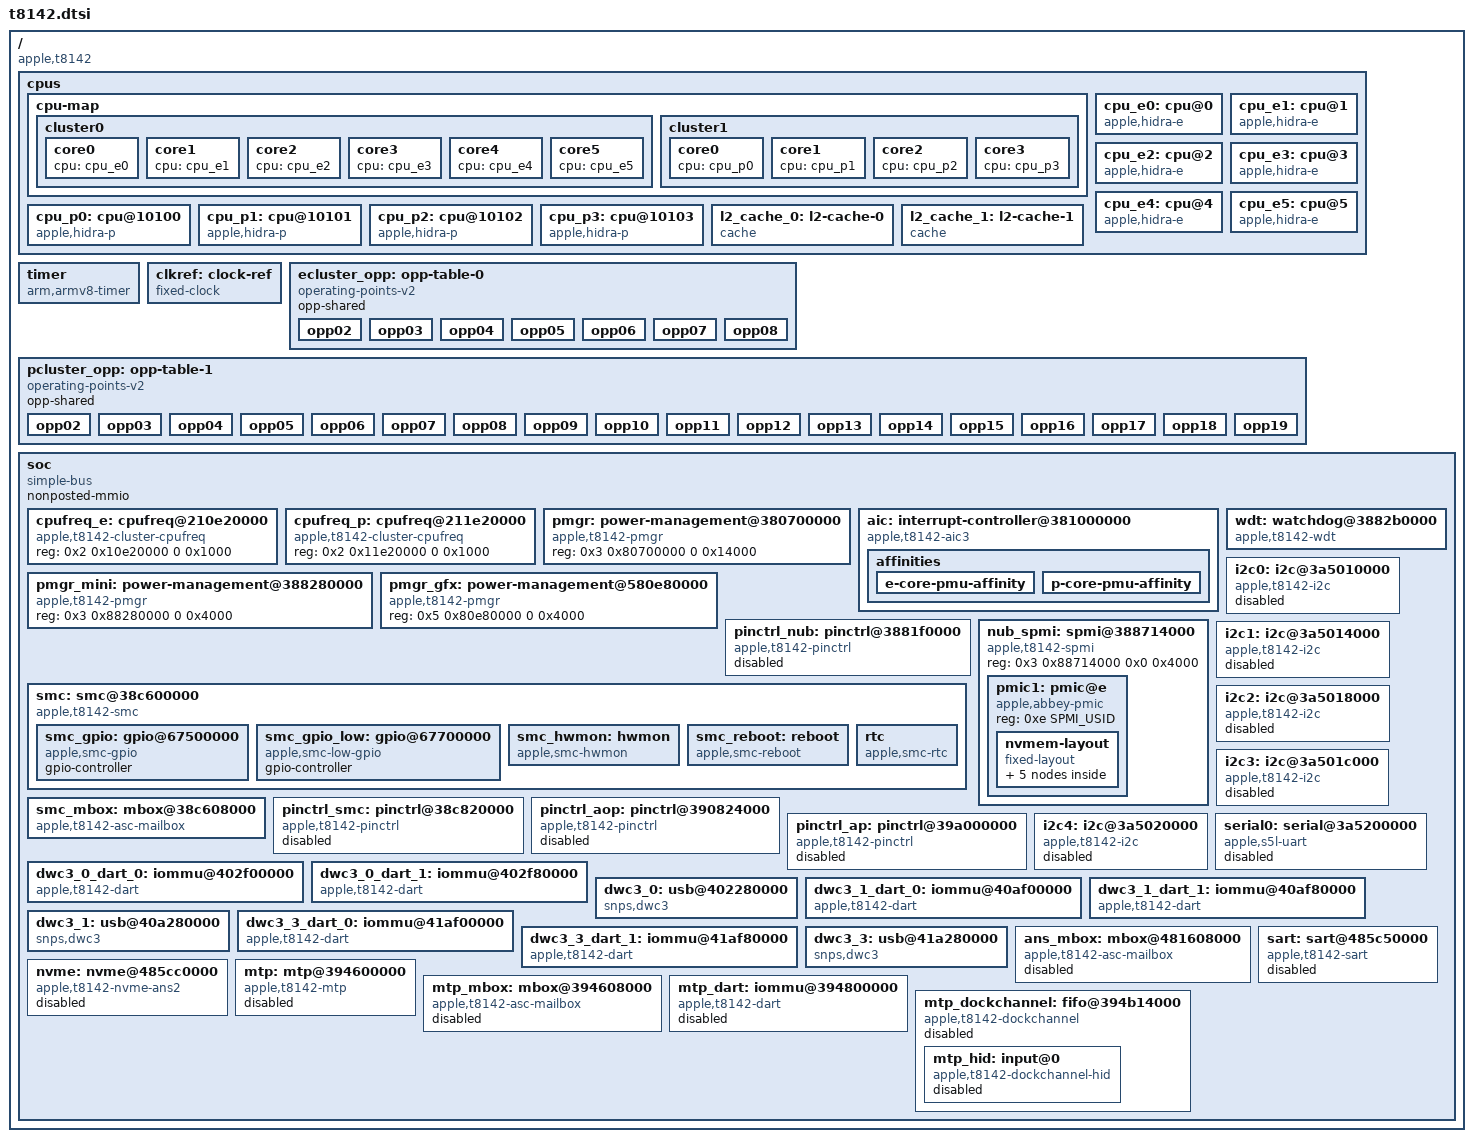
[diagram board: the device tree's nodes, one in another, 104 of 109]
// SPDX-License-Identifier: GPL-2.0+ OR MIT
/*
 * Apple T8142 "M5" SoC
 *
 * Minimal bring-up tree derived from the J704 ADT (macOS 27.0) and t8132.dtsi.
 * Power domains come from t8142-pmgr.dtsi (generated from the ADT).
 */

#include <dt-bindings/interrupt-controller/apple-aic.h>
#include <dt-bindings/interrupt-controller/irq.h>
#include <dt-bindings/pinctrl/apple.h>
#include <dt-bindings/spmi/spmi.h>

/ {
	compatible = "apple,t8142", "apple,arm-platform";

	#address-cells = <2>;
	#size-cells = <2>;

	cpus {
		#address-cells = <2>;
		#size-cells = <0>;

		cpu-map {
			cluster0 {
				core0 {
					cpu = <&cpu_e0>;
				};
				core1 {
					cpu = <&cpu_e1>;
				};
				core2 {
					cpu = <&cpu_e2>;
				};
				core3 {
					cpu = <&cpu_e3>;
				};
				core4 {
					cpu = <&cpu_e4>;
				};
				core5 {
					cpu = <&cpu_e5>;
				};
			};

			cluster1 {
				core0 {
					cpu = <&cpu_p0>;
				};
				core1 {
					cpu = <&cpu_p1>;
				};
				core2 {
					cpu = <&cpu_p2>;
				};
				core3 {
					cpu = <&cpu_p3>;
				};
			};
		};

		cpu_e0: cpu@0 {
			compatible = "apple,hidra-e";
			device_type = "cpu";
			reg = <0x0 0x0>;
			enable-method = "spin-table";
			cpu-release-addr = <0 0>; /* to be filled by loader */
			operating-points-v2 = <&ecluster_opp>;
			performance-domains = <&cpufreq_e>;
			next-level-cache = <&l2_cache_0>;
		};

		cpu_e1: cpu@1 {
			compatible = "apple,hidra-e";
			device_type = "cpu";
			reg = <0x0 0x1>;
			enable-method = "spin-table";
			cpu-release-addr = <0 0>;
			operating-points-v2 = <&ecluster_opp>;
			performance-domains = <&cpufreq_e>;
			next-level-cache = <&l2_cache_0>;
		};

		cpu_e2: cpu@2 {
			compatible = "apple,hidra-e";
			device_type = "cpu";
			reg = <0x0 0x2>;
			enable-method = "spin-table";
			cpu-release-addr = <0 0>;
			operating-points-v2 = <&ecluster_opp>;
			performance-domains = <&cpufreq_e>;
			next-level-cache = <&l2_cache_0>;
		};

		cpu_e3: cpu@3 {
			compatible = "apple,hidra-e";
			device_type = "cpu";
			reg = <0x0 0x3>;
			enable-method = "spin-table";
			cpu-release-addr = <0 0>;
			operating-points-v2 = <&ecluster_opp>;
			performance-domains = <&cpufreq_e>;
			next-level-cache = <&l2_cache_0>;
		};

		cpu_e4: cpu@4 {
			compatible = "apple,hidra-e";
			device_type = "cpu";
			reg = <0x0 0x4>;
			enable-method = "spin-table";
			cpu-release-addr = <0 0>;
			operating-points-v2 = <&ecluster_opp>;
			performance-domains = <&cpufreq_e>;
			next-level-cache = <&l2_cache_0>;
		};

		cpu_e5: cpu@5 {
			compatible = "apple,hidra-e";
			device_type = "cpu";
			reg = <0x0 0x5>;
			enable-method = "spin-table";
			cpu-release-addr = <0 0>;
			operating-points-v2 = <&ecluster_opp>;
			performance-domains = <&cpufreq_e>;
			next-level-cache = <&l2_cache_0>;
		};

		cpu_p0: cpu@10100 {
			compatible = "apple,hidra-p";
			device_type = "cpu";
			reg = <0x0 0x10100>;
			enable-method = "spin-table";
			cpu-release-addr = <0 0>;
			operating-points-v2 = <&pcluster_opp>;
			performance-domains = <&cpufreq_p>;
			next-level-cache = <&l2_cache_1>;
		};

		cpu_p1: cpu@10101 {
			compatible = "apple,hidra-p";
			device_type = "cpu";
			reg = <0x0 0x10101>;
			enable-method = "spin-table";
			cpu-release-addr = <0 0>;
			operating-points-v2 = <&pcluster_opp>;
			performance-domains = <&cpufreq_p>;
			next-level-cache = <&l2_cache_1>;
		};

		cpu_p2: cpu@10102 {
			compatible = "apple,hidra-p";
			device_type = "cpu";
			reg = <0x0 0x10102>;
			enable-method = "spin-table";
			cpu-release-addr = <0 0>;
			operating-points-v2 = <&pcluster_opp>;
			performance-domains = <&cpufreq_p>;
			next-level-cache = <&l2_cache_1>;
		};

		cpu_p3: cpu@10103 {
			compatible = "apple,hidra-p";
			device_type = "cpu";
			reg = <0x0 0x10103>;
			enable-method = "spin-table";
			cpu-release-addr = <0 0>;
			operating-points-v2 = <&pcluster_opp>;
			performance-domains = <&cpufreq_p>;
			next-level-cache = <&l2_cache_1>;
		};

		l2_cache_0: l2-cache-0 {
			compatible = "cache";
			cache-level = <2>;
			cache-unified;
			cache-size = <0x600000>;
		};

		l2_cache_1: l2-cache-1 {
			compatible = "cache";
			cache-level = <2>;
			cache-unified;
			cache-size = <0x1000000>;
		};
	};

	timer {
		compatible = "arm,armv8-timer";
		interrupt-parent = <&aic>;
		interrupt-names = "phys", "virt", "hyp-phys", "hyp-virt";
		interrupts = <AIC_FIQ AIC_TMR_GUEST_PHYS IRQ_TYPE_LEVEL_HIGH>,
		             <AIC_FIQ AIC_TMR_GUEST_VIRT IRQ_TYPE_LEVEL_HIGH>,
		             <AIC_FIQ AIC_TMR_HV_PHYS IRQ_TYPE_LEVEL_HIGH>,
		             <AIC_FIQ AIC_TMR_HV_VIRT IRQ_TYPE_LEVEL_HIGH>;
	};

	clkref: clock-ref {
		compatible = "fixed-clock";
		#clock-cells = <0>;
		clock-frequency = <24000000>;
		clock-output-names = "clkref";
	};

	/*
	 * DVFS states from the ADT (/arm-io/pmgr voltage-states1-sram for the E
	 * cluster, voltage-states5-sram for the P cluster); opp-level = P-state.
	 * clock-latency-ns is a conservative estimate, not measured.
	 * P-state 1 is left out: with the ADT's 972/1308 MHz it benchmarks like
	 * ~320-330 MHz on both clusters (#244), unlike states 2+ which scale linearly.
	 * The P cluster also clamps requests above P-state 15 (4272 MHz) here.
	 */
	ecluster_opp: opp-table-0 {
		compatible = "operating-points-v2";
		opp-shared;

		opp02 {
			opp-hz = /bits/ 64 <1152000000>;
			opp-level = <2>;
			clock-latency-ns = <50000>;
		};

		opp03 {
			opp-hz = /bits/ 64 <1584000000>;
			opp-level = <3>;
			clock-latency-ns = <50000>;
		};

		opp04 {
			opp-hz = /bits/ 64 <1992000000>;
			opp-level = <4>;
			clock-latency-ns = <50000>;
		};

		opp05 {
			opp-hz = /bits/ 64 <2352000000>;
			opp-level = <5>;
			clock-latency-ns = <50000>;
		};

		opp06 {
			opp-hz = /bits/ 64 <2700000000>;
			opp-level = <6>;
			clock-latency-ns = <50000>;
		};

		opp07 {
			opp-hz = /bits/ 64 <2964000000>;
			opp-level = <7>;
			clock-latency-ns = <50000>;
		};

		opp08 {
			opp-hz = /bits/ 64 <3048000000>;
			opp-level = <8>;
			clock-latency-ns = <50000>;
		};
	};

	pcluster_opp: opp-table-1 {
		compatible = "operating-points-v2";
		opp-shared;

		opp02 {
			opp-hz = /bits/ 64 <1608000000>;
			opp-level = <2>;
			clock-latency-ns = <50000>;
		};

		opp03 {
			opp-hz = /bits/ 64 <1932000000>;
			opp-level = <3>;
			clock-latency-ns = <50000>;
		};

		opp04 {
			opp-hz = /bits/ 64 <2220000000>;
			opp-level = <4>;
			clock-latency-ns = <50000>;
		};

		opp05 {
			opp-hz = /bits/ 64 <2508000000>;
			opp-level = <5>;
			clock-latency-ns = <50000>;
		};

		opp06 {
			opp-hz = /bits/ 64 <2820000000>;
			opp-level = <6>;
			clock-latency-ns = <50000>;
		};

		opp07 {
			opp-hz = /bits/ 64 <3072000000>;
			opp-level = <7>;
			clock-latency-ns = <50000>;
		};

		opp08 {
			opp-hz = /bits/ 64 <3300000000>;
			opp-level = <8>;
			clock-latency-ns = <50000>;
		};

		opp09 {
			opp-hz = /bits/ 64 <3516000000>;
			opp-level = <9>;
			clock-latency-ns = <50000>;
		};

		opp10 {
			opp-hz = /bits/ 64 <3720000000>;
			opp-level = <10>;
			clock-latency-ns = <50000>;
		};

		opp11 {
			opp-hz = /bits/ 64 <3876000000>;
			opp-level = <11>;
			clock-latency-ns = <50000>;
		};

		opp12 {
			opp-hz = /bits/ 64 <4020000000>;
			opp-level = <12>;
			clock-latency-ns = <50000>;
		};

		opp13 {
			opp-hz = /bits/ 64 <4176000000>;
			opp-level = <13>;
			clock-latency-ns = <50000>;
		};

		opp14 {
			opp-hz = /bits/ 64 <4248000000>;
			opp-level = <14>;
			clock-latency-ns = <50000>;
		};

		opp15 {
			opp-hz = /bits/ 64 <4272000000>;
			opp-level = <15>;
			clock-latency-ns = <50000>;
		};

		opp16 {
			opp-hz = /bits/ 64 <4332000000>;
			opp-level = <16>;
			clock-latency-ns = <50000>;
		};

		opp17 {
			opp-hz = /bits/ 64 <4428000000>;
			opp-level = <17>;
			clock-latency-ns = <50000>;
		};

		opp18 {
			opp-hz = /bits/ 64 <4512000000>;
			opp-level = <18>;
			clock-latency-ns = <50000>;
		};

		opp19 {
			opp-hz = /bits/ 64 <4608000000>;
			opp-level = <19>;
			clock-latency-ns = <50000>;
		};
	};

	soc: soc {
		compatible = "simple-bus";
		#address-cells = <2>;
		#size-cells = <2>;

		ranges;
		nonposted-mmio;

		cpufreq_e: cpufreq@210e20000 {
			compatible = "apple,t8142-cluster-cpufreq", "apple,t8112-cluster-cpufreq",
				     "apple,cluster-cpufreq";
			reg = <0x2 0x10e20000 0 0x1000>;
			#performance-domain-cells = <0>;
		};

		cpufreq_p: cpufreq@211e20000 {
			compatible = "apple,t8142-cluster-cpufreq", "apple,t8112-cluster-cpufreq",
				     "apple,cluster-cpufreq";
			reg = <0x2 0x11e20000 0 0x1000>;
			#performance-domain-cells = <0>;
		};

		pmgr: power-management@380700000 {
			compatible = "apple,t8142-pmgr", "apple,t8103-pmgr", "syscon", "simple-mfd";
			#address-cells = <1>;
			#size-cells = <1>;
			reg = <0x3 0x80700000 0 0x14000>;
		};

		aic: interrupt-controller@381000000 {
			compatible = "apple,t8142-aic3", "apple,t8122-aic3";
			#interrupt-cells = <3>;
			interrupt-controller;
			reg = <0x00000003 0x81000000 0x00000000 0x1cc000>,
			      <0x00000003 0x81040000 0x00000000 0x4000>;
			reg-names = "core", "event";
			power-domains = <&ps_aic>;

			affinities {
				e-core-pmu-affinity {
					apple,fiq-index = <AIC_CPU_PMU_E>;
					cpus = <&cpu_e0 &cpu_e1 &cpu_e2 &cpu_e3 &cpu_e4 &cpu_e5>;
				};

				p-core-pmu-affinity {
					apple,fiq-index = <AIC_CPU_PMU_P>;
					cpus = <&cpu_p0 &cpu_p1 &cpu_p2 &cpu_p3>;
				};
			};
		};

		pmgr_mini: power-management@388280000 {
			compatible = "apple,t8142-pmgr", "apple,t8103-pmgr", "syscon", "simple-mfd";
			#address-cells = <1>;
			#size-cells = <1>;
			reg = <0x3 0x88280000 0 0x4000>;
		};

		pmgr_gfx: power-management@580e80000 {
			compatible = "apple,t8142-pmgr", "apple,t8103-pmgr", "syscon", "simple-mfd";
			#address-cells = <1>;
			#size-cells = <1>;
			reg = <0x5 0x80e80000 0 0x4000>;
		};

		wdt: watchdog@3882b0000 {
			compatible = "apple,t8142-wdt", "apple,t8103-wdt";
			reg = <0x3 0x882b0000 0x0 0x4000>;
			clocks = <&clkref>;
			interrupt-parent = <&aic>;
			interrupts = <AIC_IRQ 361 IRQ_TYPE_LEVEL_HIGH>;
		};

		pinctrl_nub: pinctrl@3881f0000 {
			compatible = "apple,t8142-pinctrl", "apple,t8103-pinctrl";
			reg = <0x3 0x881f0000 0x0 0x4000>;
			power-domains = <&ps_nub_gpio>;

			gpio-controller;
			#gpio-cells = <2>;
			gpio-ranges = <&pinctrl_nub 0 0 32>;
			apple,npins = <32>;

			interrupt-controller;
			#interrupt-cells = <2>;
			interrupt-parent = <&aic>;
			interrupts = <AIC_IRQ 574 IRQ_TYPE_LEVEL_HIGH>,
			             <AIC_IRQ 575 IRQ_TYPE_LEVEL_HIGH>,
			             <AIC_IRQ 576 IRQ_TYPE_LEVEL_HIGH>,
			             <AIC_IRQ 577 IRQ_TYPE_LEVEL_HIGH>,
			             <AIC_IRQ 578 IRQ_TYPE_LEVEL_HIGH>,
			             <AIC_IRQ 579 IRQ_TYPE_LEVEL_HIGH>,
			             <AIC_IRQ 580 IRQ_TYPE_LEVEL_HIGH>;
			status = "disabled"; /* npins unverified on T8142 */
		};

		/*
		 * From the ADT: nub-spmi0 (pmu-main, "pmu,abbey" at USID 0xe) and smc
		 * (ascwrap-v6, IRQs 633-636, shared SRAM = iop-smc-nub region-base/size).
		 * The PMU scratchpad offsets (info-rtc_scrpad 0x2100, info-pm_setting,
		 * info-fault_shadow, info-scrpad_socd, info-leg_scrpad) match t6031.
		 * The legacy scratchpad cells (boot_stage etc.) follow t6031 too
		 * (info-leg_scrpad 0xf800).
		 */
		nub_spmi: spmi@388714000 {
			/* generation 4 (ADT gen = 4): not register compatible with t8103 */
			compatible = "apple,t8142-spmi";
			reg = <0x3 0x88714000 0x0 0x4000>;
			#address-cells = <2>;
			#size-cells = <0>;

			pmic1: pmic@e {
				compatible = "apple,abbey-pmic", "apple,spmi-nvmem";
				reg = <0xe SPMI_USID>;

				nvmem-layout {
					compatible = "fixed-layout";
					#address-cells = <1>;
					#size-cells = <1>;

					rtc_offset: rtc-offset@2100 {
						reg = <0x2100 0x6>;
					};

					boot_stage: boot-stage@f801 {
						reg = <0xf801 0x1>;
					};

					boot_error_count: boot-error-count@f802,0 {
						reg = <0xf802 0x1>;
						bits = <0 4>;
					};

					panic_count: panic-count@f802,4 {
						reg = <0xf802 0x1>;
						bits = <4 4>;
					};

					shutdown_flag: shutdown-flag@f80f,3 {
						reg = <0xf80f 0x1>;
						bits = <3 1>;
					};
				};
			};
		};

		smc: smc@38c600000 {
			compatible = "apple,t8142-smc", "apple,smc";
			reg = <0x3 0x8c600000 0x0 0x4000>,
			      <0x3 0x8de00000 0x0 0x120000>;
			reg-names = "smc", "sram";
			mboxes = <&smc_mbox>;

			smc_gpio: gpio@67500000 {
				compatible = "apple,smc-gpio";
				gpio-controller;
				#gpio-cells = <2>;
			};

			smc_gpio_low: gpio@67700000 {
				compatible = "apple,smc-low-gpio";
				gpio-controller;
				#gpio-cells = <2>;
			};

			smc_hwmon: hwmon {
				compatible = "apple,smc-hwmon";
			};

			smc_reboot: reboot {
				compatible = "apple,smc-reboot";
				nvmem-cells = <&shutdown_flag>, <&boot_stage>,
					      <&boot_error_count>, <&panic_count>;
				nvmem-cell-names = "shutdown_flag", "boot_stage",
						   "boot_error_count", "panic_count";
			};

			rtc {
				compatible = "apple,smc-rtc";
				nvmem-cells = <&rtc_offset>;
				nvmem-cell-names = "rtc_offset";
			};
		};

		smc_mbox: mbox@38c608000 {
			compatible = "apple,t8142-asc-mailbox", "apple,asc-mailbox-v4";
			reg = <0x3 0x8c608000 0x0 0x4000>;
			interrupt-parent = <&aic>;
			interrupts = <AIC_IRQ 633 IRQ_TYPE_LEVEL_HIGH>,
				     <AIC_IRQ 634 IRQ_TYPE_LEVEL_HIGH>,
				     <AIC_IRQ 635 IRQ_TYPE_LEVEL_HIGH>,
				     <AIC_IRQ 636 IRQ_TYPE_LEVEL_HIGH>;
			interrupt-names = "send-empty", "send-not-empty",
					  "recv-empty", "recv-not-empty";
			#mbox-cells = <0>;
		};

		pinctrl_smc: pinctrl@38c820000 {
			compatible = "apple,t8142-pinctrl", "apple,t8103-pinctrl";
			reg = <0x3 0x8c820000 0x0 0x4000>;

			gpio-controller;
			#gpio-cells = <2>;
			gpio-ranges = <&pinctrl_smc 0 0 18>;
			apple,npins = <18>;

			interrupt-controller;
			#interrupt-cells = <2>;
			interrupt-parent = <&aic>;
			interrupts = <AIC_IRQ 624 IRQ_TYPE_LEVEL_HIGH>,
			             <AIC_IRQ 625 IRQ_TYPE_LEVEL_HIGH>,
			             <AIC_IRQ 626 IRQ_TYPE_LEVEL_HIGH>,
			             <AIC_IRQ 627 IRQ_TYPE_LEVEL_HIGH>,
			             <AIC_IRQ 628 IRQ_TYPE_LEVEL_HIGH>,
			             <AIC_IRQ 629 IRQ_TYPE_LEVEL_HIGH>,
			             <AIC_IRQ 630 IRQ_TYPE_LEVEL_HIGH>;
			status = "disabled"; /* npins unverified on T8142 */
		};

		pinctrl_aop: pinctrl@390824000 {
			compatible = "apple,t8142-pinctrl", "apple,t8103-pinctrl";
			reg = <0x3 0x90824000 0x0 0x4000>;

			gpio-controller;
			#gpio-cells = <2>;
			gpio-ranges = <&pinctrl_aop 0 0 57>;
			apple,npins = <57>;

			interrupt-controller;
			#interrupt-cells = <2>;
			interrupt-parent = <&aic>;
			interrupts = <AIC_IRQ 480 IRQ_TYPE_LEVEL_HIGH>,
			             <AIC_IRQ 481 IRQ_TYPE_LEVEL_HIGH>,
			             <AIC_IRQ 482 IRQ_TYPE_LEVEL_HIGH>,
			             <AIC_IRQ 483 IRQ_TYPE_LEVEL_HIGH>,
			             <AIC_IRQ 484 IRQ_TYPE_LEVEL_HIGH>,
			             <AIC_IRQ 485 IRQ_TYPE_LEVEL_HIGH>,
			             <AIC_IRQ 486 IRQ_TYPE_LEVEL_HIGH>;
			status = "disabled"; /* npins unverified on T8142 */
		};

		pinctrl_ap: pinctrl@39a000000 {
			compatible = "apple,t8142-pinctrl", "apple,t8103-pinctrl";
			reg = <0x3 0x9a000000 0x0 0x100000>;
			power-domains = <&ps_gpio>;

			gpio-controller;
			#gpio-cells = <2>;
			gpio-ranges = <&pinctrl_ap 0 0 224>;
			apple,npins = <224>;

			interrupt-controller;
			#interrupt-cells = <2>;
			interrupt-parent = <&aic>;
			interrupts = <AIC_IRQ 347 IRQ_TYPE_LEVEL_HIGH>,
			             <AIC_IRQ 348 IRQ_TYPE_LEVEL_HIGH>,
			             <AIC_IRQ 349 IRQ_TYPE_LEVEL_HIGH>,
			             <AIC_IRQ 350 IRQ_TYPE_LEVEL_HIGH>,
			             <AIC_IRQ 351 IRQ_TYPE_LEVEL_HIGH>,
			             <AIC_IRQ 352 IRQ_TYPE_LEVEL_HIGH>,
			             <AIC_IRQ 353 IRQ_TYPE_LEVEL_HIGH>;
			status = "disabled"; /* npins unverified on T8142 */
		};

		i2c0: i2c@3a5010000 {
			compatible = "apple,t8142-i2c", "apple,t8103-i2c";
			reg = <0x3 0xa5010000 0x0 0x4000>;
			power-domains = <&ps_i2c0>;
			clocks = <&clkref>;
			interrupt-parent = <&aic>;
			interrupts = <AIC_IRQ 1247 IRQ_TYPE_LEVEL_HIGH>;
			#address-cells = <0x1>;
			#size-cells = <0x0>;
			status = "disabled";
		};

		i2c1: i2c@3a5014000 {
			compatible = "apple,t8142-i2c", "apple,t8103-i2c";
			reg = <0x3 0xa5014000 0x0 0x4000>;
			power-domains = <&ps_i2c1>;
			clocks = <&clkref>;
			interrupt-parent = <&aic>;
			interrupts = <AIC_IRQ 1248 IRQ_TYPE_LEVEL_HIGH>;
			#address-cells = <0x1>;
			#size-cells = <0x0>;
			status = "disabled";
		};

		i2c2: i2c@3a5018000 {
			compatible = "apple,t8142-i2c", "apple,t8103-i2c";
			reg = <0x3 0xa5018000 0x0 0x4000>;
			power-domains = <&ps_i2c2>;
			clocks = <&clkref>;
			interrupt-parent = <&aic>;
			interrupts = <AIC_IRQ 1249 IRQ_TYPE_LEVEL_HIGH>;
			#address-cells = <0x1>;
			#size-cells = <0x0>;
			status = "disabled";
		};

		i2c3: i2c@3a501c000 {
			compatible = "apple,t8142-i2c", "apple,t8103-i2c";
			reg = <0x3 0xa501c000 0x0 0x4000>;
			power-domains = <&ps_i2c3>;
			clocks = <&clkref>;
			interrupt-parent = <&aic>;
			interrupts = <AIC_IRQ 1250 IRQ_TYPE_LEVEL_HIGH>;
			#address-cells = <0x1>;
			#size-cells = <0x0>;
			status = "disabled";
		};

		i2c4: i2c@3a5020000 {
			compatible = "apple,t8142-i2c", "apple,t8103-i2c";
			reg = <0x3 0xa5020000 0x0 0x4000>;
			power-domains = <&ps_i2c4>;
			clocks = <&clkref>;
			interrupt-parent = <&aic>;
			interrupts = <AIC_IRQ 1251 IRQ_TYPE_LEVEL_HIGH>;
			#address-cells = <0x1>;
			#size-cells = <0x0>;
			status = "disabled";
		};

		serial0: serial@3a5200000 {
			compatible = "apple,s5l-uart";
			reg = <0x3 0xa5200000 0x0 0x1000>;
			power-domains = <&ps_uart0>;
			reg-io-width = <4>;
			interrupt-parent = <&aic>;
			interrupts = <AIC_IRQ 1231 IRQ_TYPE_LEVEL_HIGH>;
			clocks = <&clkref>, <&clkref>;
			clock-names = "uart", "clk_uart_baud0";
			status = "disabled";
		};

		/*
		 * USB2 gadget-only bring-up: plain DWC3 core on the PHY state m1n1 leaves
		 * behind (USB2 PHY running, pipehandler in dummy mux). No ATC PHY / tipd
		 * driver yet, so no host mode, no SuperSpeed and no role switching.
		 */

		dwc3_0_dart_0: iommu@402f00000 {
			compatible = "apple,t8142-dart", "apple,t8110-dart";
			reg = <0x4 0x02f00000 0x0 0x4000>;
			interrupt-parent = <&aic>;
			interrupts = <AIC_IRQ 1515 IRQ_TYPE_LEVEL_HIGH>;
			power-domains = <&ps_atc0_usb>;
			#iommu-cells = <1>;
		};

		dwc3_0_dart_1: iommu@402f80000 {
			compatible = "apple,t8142-dart", "apple,t8110-dart";
			reg = <0x4 0x02f80000 0x0 0x4000>;
			interrupt-parent = <&aic>;
			interrupts = <AIC_IRQ 1515 IRQ_TYPE_LEVEL_HIGH>;
			power-domains = <&ps_atc0_usb>;
			#iommu-cells = <1>;
		};

		dwc3_0: usb@402280000 {
			compatible = "snps,dwc3";
			reg = <0x4 0x02280000 0x0 0xcd00>;
			interrupt-parent = <&aic>;
			interrupts = <AIC_IRQ 1511 IRQ_TYPE_LEVEL_HIGH>;
			dr_mode = "peripheral";
			maximum-speed = "high-speed";
			snps,dis_u2_susphy_quirk;
			snps,dis_u3_susphy_quirk;
			iommus = <&dwc3_0_dart_0 0>, <&dwc3_0_dart_1 1>;
			power-domains = <&ps_atc0_usb>;
		};

		dwc3_1_dart_0: iommu@40af00000 {
			compatible = "apple,t8142-dart", "apple,t8110-dart";
			reg = <0x4 0x0af00000 0x0 0x4000>;
			interrupt-parent = <&aic>;
			interrupts = <AIC_IRQ 1578 IRQ_TYPE_LEVEL_HIGH>;
			power-domains = <&ps_atc1_usb>;
			#iommu-cells = <1>;
		};

		dwc3_1_dart_1: iommu@40af80000 {
			compatible = "apple,t8142-dart", "apple,t8110-dart";
			reg = <0x4 0x0af80000 0x0 0x4000>;
			interrupt-parent = <&aic>;
			interrupts = <AIC_IRQ 1578 IRQ_TYPE_LEVEL_HIGH>;
			power-domains = <&ps_atc1_usb>;
			#iommu-cells = <1>;
		};

		dwc3_1: usb@40a280000 {
			compatible = "snps,dwc3";
			reg = <0x4 0x0a280000 0x0 0xcd00>;
			interrupt-parent = <&aic>;
			interrupts = <AIC_IRQ 1574 IRQ_TYPE_LEVEL_HIGH>;
			dr_mode = "peripheral";
			maximum-speed = "high-speed";
			snps,dis_u2_susphy_quirk;
			snps,dis_u3_susphy_quirk;
			iommus = <&dwc3_1_dart_0 0>, <&dwc3_1_dart_1 1>;
			power-domains = <&ps_atc1_usb>;
		};

		dwc3_3_dart_0: iommu@41af00000 {
			compatible = "apple,t8142-dart", "apple,t8110-dart";
			reg = <0x4 0x1af00000 0x0 0x4000>;
			interrupt-parent = <&aic>;
			interrupts = <AIC_IRQ 1704 IRQ_TYPE_LEVEL_HIGH>;
			power-domains = <&ps_atc3_usb>;
			#iommu-cells = <1>;
		};

		dwc3_3_dart_1: iommu@41af80000 {
			compatible = "apple,t8142-dart", "apple,t8110-dart";
			reg = <0x4 0x1af80000 0x0 0x4000>;
			interrupt-parent = <&aic>;
			interrupts = <AIC_IRQ 1704 IRQ_TYPE_LEVEL_HIGH>;
			power-domains = <&ps_atc3_usb>;
			#iommu-cells = <1>;
		};

		dwc3_3: usb@41a280000 {
			compatible = "snps,dwc3";
			reg = <0x4 0x1a280000 0x0 0xcd00>;
			interrupt-parent = <&aic>;
			interrupts = <AIC_IRQ 1700 IRQ_TYPE_LEVEL_HIGH>;
			dr_mode = "peripheral";
			maximum-speed = "high-speed";
			snps,dis_u2_susphy_quirk;
			snps,dis_u3_susphy_quirk;
			iommus = <&dwc3_3_dart_0 0>, <&dwc3_3_dart_1 1>;
			power-domains = <&ps_atc3_usb>;
		};

		/*
		 * ANS2 (ADT /arm-io/ans, ascwrap-v6, role ANS2) and its SART
		 * (sart-version 3). Same ASC and SART addresses as T8132. The
		 * NVMe BAR is ans reg[3] (0x60000; reg[9] at +0x40000000 is an
		 * alias, only 0x10000 in the ADT). Probed read-only through
		 * m1n1 (#191): BOOT_STATUS 0xde71ce55, VS 1.1. IRQs: ans
		 * interrupts[0..3] (mailbox, ascending as on T8103/T8132) and
		 * [nvme-interrupt-idx = 4].
		 */
		ans_mbox: mbox@481608000 {
			compatible = "apple,t8142-asc-mailbox", "apple,asc-mailbox-v4";
			reg = <0x4 0x81608000 0x0 0x4000>;
			interrupt-parent = <&aic>;
			interrupts = <AIC_IRQ 1143 IRQ_TYPE_LEVEL_HIGH>,
				     <AIC_IRQ 1144 IRQ_TYPE_LEVEL_HIGH>,
				     <AIC_IRQ 1145 IRQ_TYPE_LEVEL_HIGH>,
				     <AIC_IRQ 1146 IRQ_TYPE_LEVEL_HIGH>;
			interrupt-names = "send-empty", "send-not-empty",
					  "recv-empty", "recv-not-empty";
			#mbox-cells = <0>;
			power-domains = <&ps_ans>;
			status = "disabled";
		};

		sart: sart@485c50000 {
			compatible = "apple,t8142-sart", "apple,t6000-sart";
			reg = <0x4 0x85c50000 0x0 0xc000>;
			power-domains = <&ps_ans>;
			status = "disabled";
		};

		nvme: nvme@485cc0000 {
			compatible = "apple,t8142-nvme-ans2", "apple,t8132-nvme-ans2";
			reg = <0x4 0x85cc0000 0x0 0x60000>,
			      <0x4 0x81600000 0x0 0x4000>;
			reg-names = "nvme", "ans";
			interrupt-parent = <&aic>;
			interrupts = <AIC_IRQ 1155 IRQ_TYPE_LEVEL_HIGH>;
			mboxes = <&ans_mbox>;
			apple,sart = <&sart>;
			power-domains = <&ps_ans>, <&ps_apcie_sys_st>;
			power-domain-names = "ans", "apcie0";
			resets = <&ps_ans>;
			status = "disabled";
		};

		/*
		 * MTP (keyboard/trackpad coprocessor): ADT /arm-io/mtp (ascwrap-v6,
		 * iop-mtp-nub pre-loaded), dart-mtp (t8110, remap 1,2,3 -> 0) and
		 * dockchannel-mtp (fifo-size 2048). Same addresses as T8132;
		 * the IRQs are T8142's (mtp [1300, 1299, 1302, 1301] ascending,
		 * dockchannel 1277, dart 1275).
		 */
		mtp: mtp@394600000 {
			compatible = "apple,t8142-mtp", "apple,t8132-mtp",
				     "apple,t8132-rtk-helper-asc4",
				     "apple,mtp", "apple,rtk-helper-asc4";
			reg = <0x3 0x94600000 0x0 0x4000>;
			reg-names = "asc";
			mboxes = <&mtp_mbox>;
			iommus = <&mtp_dart 0>;
			#helper-cells = <0>;
			status = "disabled";
		};

		mtp_mbox: mbox@394608000 {
			compatible = "apple,t8142-asc-mailbox", "apple,asc-mailbox-v4";
			reg = <0x3 0x94608000 0x0 0x4000>;
			interrupt-parent = <&aic>;
			interrupts = <AIC_IRQ 1299 IRQ_TYPE_LEVEL_HIGH>,
				     <AIC_IRQ 1300 IRQ_TYPE_LEVEL_HIGH>,
				     <AIC_IRQ 1301 IRQ_TYPE_LEVEL_HIGH>,
				     <AIC_IRQ 1302 IRQ_TYPE_LEVEL_HIGH>;
			interrupt-names = "send-empty", "send-not-empty",
					  "recv-empty", "recv-not-empty";
			#mbox-cells = <0>;
			status = "disabled";
		};

		mtp_dart: iommu@394800000 {
			compatible = "apple,t8142-dart", "apple,t8132-dart", "apple,t8110-dart";
			reg = <0x3 0x94800000 0x0 0xc000>;
			interrupt-parent = <&aic>;
			interrupts = <AIC_IRQ 1275 IRQ_TYPE_LEVEL_HIGH>;
			#iommu-cells = <1>;
			apple,sid-remap = <1 0>, <2 0>, <3 0>;
			status = "disabled";
		};

		mtp_dockchannel: fifo@394b14000 {
			compatible = "apple,t8142-dockchannel", "apple,dockchannel";
			reg = <0x3 0x94b14000 0x0 0x1000>;
			reg-names = "irq";
			interrupt-parent = <&aic>;
			interrupts = <AIC_IRQ 1277 IRQ_TYPE_LEVEL_HIGH>;
			ranges = <0 0x3 0x94b28000 0x10000>;
			nonposted-mmio;
			#address-cells = <1>;
			#size-cells = <1>;
			interrupt-controller;
			#interrupt-cells = <2>;
			status = "disabled";

			mtp_hid: input@0 {
				compatible = "apple,t8142-dockchannel-hid", "apple,t8132-dockchannel-hid",
					     "apple,dockchannel-hid";
				reg = <0x0000 0x1000>,
				      <0x4000 0x1000>,
				      <0x8000 0x1000>,
				      <0xc000 0x1000>;
				reg-names = "rmt-config", "rmt-data", "config", "data";
				iommus = <&mtp_dart 0>;
				interrupt-parent = <&mtp_dockchannel>;
				interrupts = <2 IRQ_TYPE_LEVEL_HIGH>,
					     <3 IRQ_TYPE_LEVEL_HIGH>;
				interrupt-names = "tx", "rx";
				apple,fifo-size = <0x800>;
				apple,helper-cpu = <&mtp>;
				status = "disabled";
			};
		};
	};
};

#include "t8142-pmgr.dtsi"
